# IPCM register map
Registers from a debugger description file.
Registers are 32-bit, access not given, no defined reset value unless marked. A register's access mark holds for its fields unless they carry their own. Addresses are absolute; registers are grouped by the start of their names; lines under a group give offsets from that group; [hi:lo] are bit positions; {n}, {i} and the like mark numbered series; 'fields as' and 'values as' point back to an identical list; <NAME> marks a mode.

## SFR
{0x4000B000+0x40*i} IPCM{i}SOURCE (i=0..2)
  [31:0] SRC_SET
{0x4000B004+0x40*i} IPCM{i}DSET wo (i=0..2)
  [31:0] DEST_SET
{0x4000B008+0x40*i} IPCM{i}DCLEAR wo (i=0..2)
  [31:0] DEST_CLR
{0x4000B00C+0x40*i} IPCM{i}DSTATUS ro (i=0..2)
  [31:0] DEST_STAT
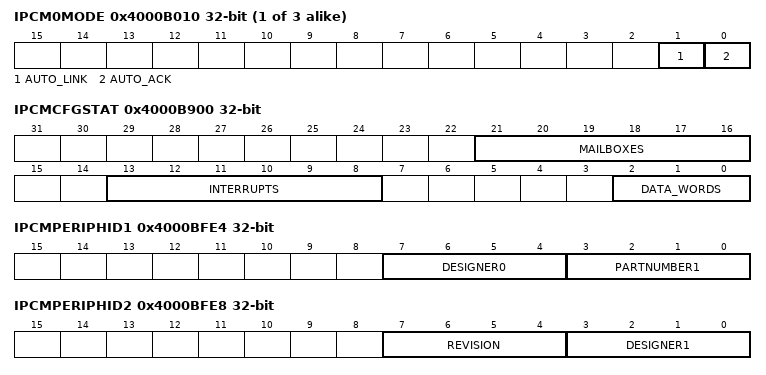
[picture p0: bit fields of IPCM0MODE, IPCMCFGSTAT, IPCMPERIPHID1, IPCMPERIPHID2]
{0x4000B010+0x40*i} IPCM{i}MODE (i=0..2)
  [1] AUTO_LINK, [0] AUTO_ACK
{0x4000B014+0x40*i} IPCM{i}MSET wo (i=0..2)
  [31:0] MASK_SET
{0x4000B018+0x40*i} IPCM{i}MCLEAR wo (i=0..2)
  [31:0] MASK_CLR
{0x4000B01C+0x40*i} IPCM{i}MSTATUS ro (i=0..2)
  [31:0] MASK_STAT
{0x4000B020+0x40*i} IPCM{i}SEND (i=0..2)
  [1:0] SEND
{0x4000B024+4i} IPCM0DR{i} (i=0..6)
  [31:0] DATA
{0x4000B064+4i} IPCM1DR{i} (i=0..6)
  [31:0] DATA
{0x4000B0A4+4i} IPCM2DR{i} (i=0..6)
  [31:0] DATA
{0x4000B800+8i} IPCMMIS{i} ro (i=0..2)
  [31:0] MASK_INT_STAT
{0x4000B804+8i} IPCMRIS{i} ro (i=0..2)
  [31:0] RAW_INT_STAT
0x4000B900 IPCMCFGSTAT ro
  [21:16] MAILBOXES, [13:8] INTERRUPTS, [2:0] DATA_WORDS
0x4000BF00 IPCMTCR
  [0] ITEN
0x4000BF04 IPCMTOR
  [31:0] INTTEST
0x4000BFE0 IPCMPERIPHID0 ro
  [7:0] PARTNUMBER0
0x4000BFE4 IPCMPERIPHID1 ro
  [7:4] DESIGNER0, [3:0] PARTNUMBER1
0x4000BFE8 IPCMPERIPHID2 ro
  [7:4] REVISION, [3:0] DESIGNER1
0x4000BFEC IPCMPERIPHID3 ro
  [7:0] CONFIG
0x4000BFF0 IPCMPCELLID0 ro
{0x4000BFF0+4i} IPCMPCELLID{i} ro (i=1..3)
  [7:0] IPCMPCELLID{i}
